# f28p65x_output_xbar_ext64_regs register map
Vendor: Texas Instruments
Peripheral module from a debugger description file (folder C2000).
Address unit: 16 bits
Registers are 32-bit, read-write, no defined reset value unless marked. A register's access mark holds for its fields unless they carry their own. Offsets are as the file gives them; lines under a group give offsets from that group; [hi:lo] are bit positions; {n}, {i} and the like mark numbered series; 'fields as' and 'values as' point back to an identical list; <NAME> marks a mode.

## OUTPUT_XBAR_EXT64_REGS — OUTPUT XBAR EXT64 Registers
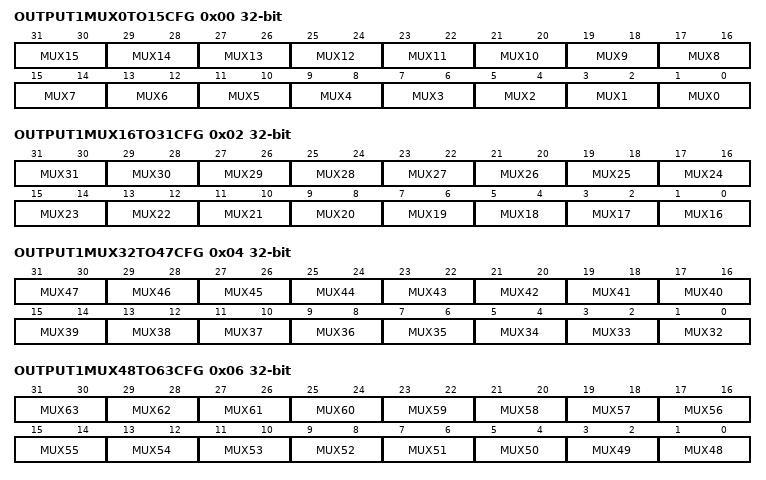
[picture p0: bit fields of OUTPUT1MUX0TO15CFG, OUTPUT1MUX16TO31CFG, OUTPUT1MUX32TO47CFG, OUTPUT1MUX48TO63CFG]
0x00 OUTPUT1MUX0TO15CFG — Output X-BAR Mux Configuration for Output 1
  [2n+1:2n] MUX{n} (n=0..15) — Mux{n} Configuration for OUTPUT1 of OUTPUT-XBAR
0x02 OUTPUT1MUX16TO31CFG — Output X-BAR Mux Configuration for Output 1
  [2n-31:2n-32] MUX{n} (n=16..31) — Mux{n} Configuration for OUTPUT1 of OUTPUT-XBAR
0x04 OUTPUT1MUX32TO47CFG — Output X-BAR Mux Configuration for Output 1
  [2n-63:2n-64] MUX{n} (n=32..47) — MUX{n} Configuration for OUTPUT1 of OUTPUT-XBAR
0x06 OUTPUT1MUX48TO63CFG — Output X-BAR Mux Configuration for Output 1
  [2n-95:2n-96] MUX{n} (n=48..63) — MUX{n} Configuration for OUTPUT1 of OUTPUT-XBAR
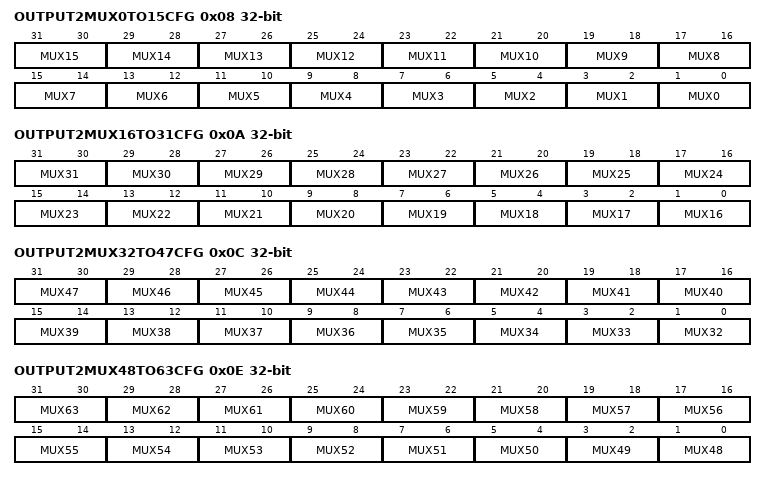
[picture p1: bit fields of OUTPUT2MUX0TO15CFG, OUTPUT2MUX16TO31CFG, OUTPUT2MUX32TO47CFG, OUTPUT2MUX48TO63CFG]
0x08 OUTPUT2MUX0TO15CFG — Output X-BAR Mux Configuration for Output 2
  [2n+1:2n] MUX{n} (n=0..15) — Mux{n} Configuration for OUTPUT2 of OUTPUT-XBAR
0x0A OUTPUT2MUX16TO31CFG — Output X-BAR Mux Configuration for Output 2
  [2n-31:2n-32] MUX{n} (n=16..31) — Mux{n} Configuration for OUTPUT2 of OUTPUT-XBAR
0x0C OUTPUT2MUX32TO47CFG — Output X-BAR Mux Configuration for Output 2
  [2n-63:2n-64] MUX{n} (n=32..47) — MUX{n} Configuration for OUTPUT2 of OUTPUT-XBAR
0x0E OUTPUT2MUX48TO63CFG — Output X-BAR Mux Configuration for Output 2
  [2n-95:2n-96] MUX{n} (n=48..63) — MUX{n} Configuration for OUTPUT2 of OUTPUT-XBAR
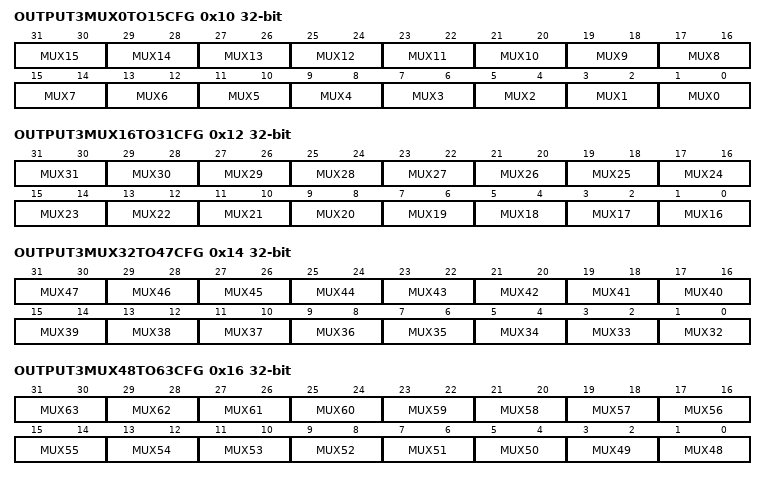
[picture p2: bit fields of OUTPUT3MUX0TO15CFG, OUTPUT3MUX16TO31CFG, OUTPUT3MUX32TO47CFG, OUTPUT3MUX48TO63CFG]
0x10 OUTPUT3MUX0TO15CFG — Output X-BAR Mux Configuration for Output 3
  [2n+1:2n] MUX{n} (n=0..15) — Mux{n} Configuration for OUTPUT3 of OUTPUT-XBAR
0x12 OUTPUT3MUX16TO31CFG — Output X-BAR Mux Configuration for Output 3
  [2n-31:2n-32] MUX{n} (n=16..31) — Mux{n} Configuration for OUTPUT3 of OUTPUT-XBAR
0x14 OUTPUT3MUX32TO47CFG — Output X-BAR Mux Configuration for Output 3
  [2n-63:2n-64] MUX{n} (n=32..47) — MUX{n} Configuration for OUTPUT3 of OUTPUT-XBAR
0x16 OUTPUT3MUX48TO63CFG — Output X-BAR Mux Configuration for Output 3
  [2n-95:2n-96] MUX{n} (n=48..63) — MUX{n} Configuration for OUTPUT3 of OUTPUT-XBAR
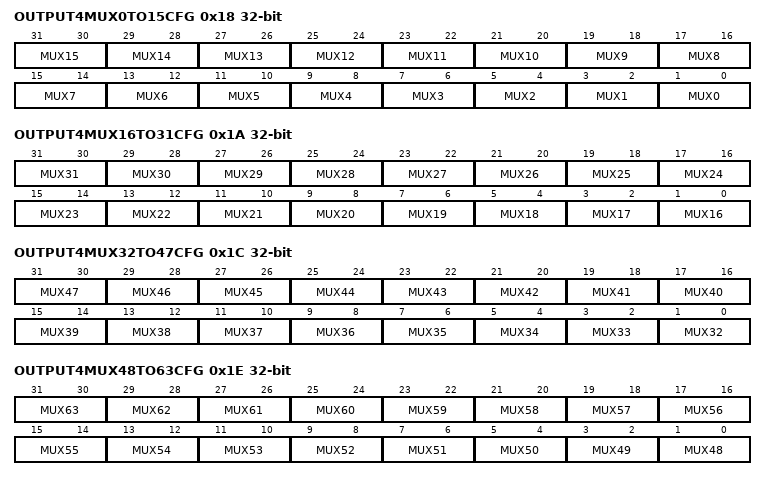
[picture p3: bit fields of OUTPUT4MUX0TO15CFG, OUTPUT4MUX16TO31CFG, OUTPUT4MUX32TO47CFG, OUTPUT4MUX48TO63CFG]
0x18 OUTPUT4MUX0TO15CFG — Output X-BAR Mux Configuration for Output 4
  [2n+1:2n] MUX{n} (n=0..15) — Mux{n} Configuration for OUTPUT4 of OUTPUT-XBAR
0x1A OUTPUT4MUX16TO31CFG — Output X-BAR Mux Configuration for Output 4
  [2n-31:2n-32] MUX{n} (n=16..31) — Mux{n} Configuration for OUTPUT4 of OUTPUT-XBAR
0x1C OUTPUT4MUX32TO47CFG — Output X-BAR Mux Configuration for Output 4
  [2n-63:2n-64] MUX{n} (n=32..47) — MUX{n} Configuration for OUTPUT4 of OUTPUT-XBAR
0x1E OUTPUT4MUX48TO63CFG — Output X-BAR Mux Configuration for Output 4
  [2n-95:2n-96] MUX{n} (n=48..63) — MUX{n} Configuration for OUTPUT4 of OUTPUT-XBAR
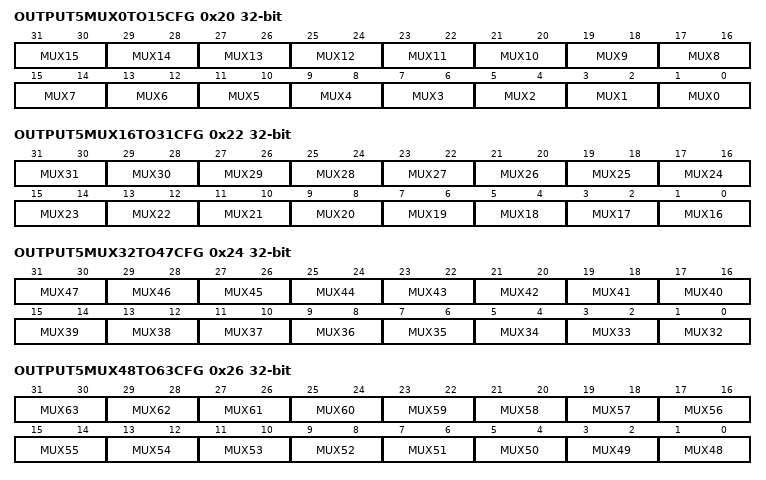
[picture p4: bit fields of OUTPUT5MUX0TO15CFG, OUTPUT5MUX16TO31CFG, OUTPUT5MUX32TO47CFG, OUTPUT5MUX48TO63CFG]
0x20 OUTPUT5MUX0TO15CFG — Output X-BAR Mux Configuration for Output 5
  [2n+1:2n] MUX{n} (n=0..15) — Mux{n} Configuration for OUTPUT5 of OUTPUT-XBAR
0x22 OUTPUT5MUX16TO31CFG — Output X-BAR Mux Configuration for Output 5
  [2n-31:2n-32] MUX{n} (n=16..31) — Mux{n} Configuration for OUTPUT5 of OUTPUT-XBAR
0x24 OUTPUT5MUX32TO47CFG — Output X-BAR Mux Configuration for Output 5
  [2n-63:2n-64] MUX{n} (n=32..47) — MUX{n} Configuration for OUTPUT5 of OUTPUT-XBAR
0x26 OUTPUT5MUX48TO63CFG — Output X-BAR Mux Configuration for Output 5
  [2n-95:2n-96] MUX{n} (n=48..63) — MUX{n} Configuration for OUTPUT5 of OUTPUT-XBAR
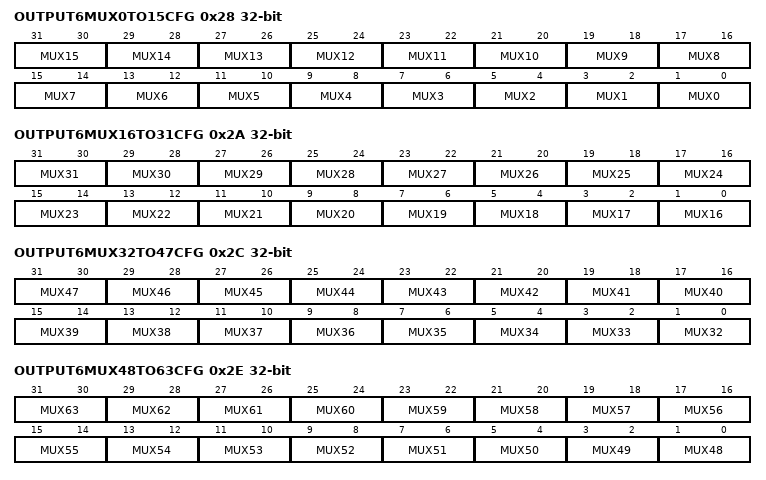
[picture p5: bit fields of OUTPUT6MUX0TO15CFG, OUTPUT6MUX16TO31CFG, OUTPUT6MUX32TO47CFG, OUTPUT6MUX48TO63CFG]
0x28 OUTPUT6MUX0TO15CFG — Output X-BAR Mux Configuration for Output 6
  [2n+1:2n] MUX{n} (n=0..15) — Mux{n} Configuration for OUTPUT6 of OUTPUT-XBAR
0x2A OUTPUT6MUX16TO31CFG — Output X-BAR Mux Configuration for Output 6
  [2n-31:2n-32] MUX{n} (n=16..31) — Mux{n} Configuration for OUTPUT6 of OUTPUT-XBAR
0x2C OUTPUT6MUX32TO47CFG — Output X-BAR Mux Configuration for Output 6
  [2n-63:2n-64] MUX{n} (n=32..47) — MUX{n} Configuration for OUTPUT6 of OUTPUT-XBAR
0x2E OUTPUT6MUX48TO63CFG — Output X-BAR Mux Configuration for Output 6
  [2n-95:2n-96] MUX{n} (n=48..63) — MUX{n} Configuration for OUTPUT6 of OUTPUT-XBAR
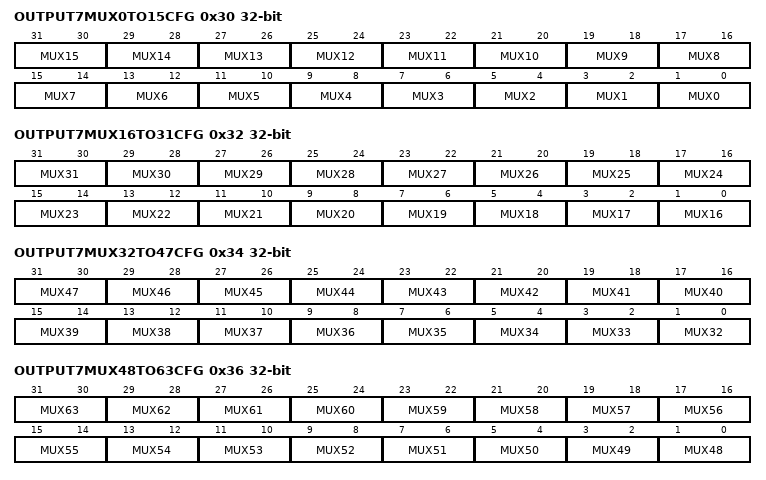
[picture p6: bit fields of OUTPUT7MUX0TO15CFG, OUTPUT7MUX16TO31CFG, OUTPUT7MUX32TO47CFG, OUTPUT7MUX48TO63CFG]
0x30 OUTPUT7MUX0TO15CFG — Output X-BAR Mux Configuration for Output 7
  [2n+1:2n] MUX{n} (n=0..15) — Mux{n} Configuration for OUTPUT7 of OUTPUT-XBAR
0x32 OUTPUT7MUX16TO31CFG — Output X-BAR Mux Configuration for Output 7
  [2n-31:2n-32] MUX{n} (n=16..31) — Mux{n} Configuration for OUTPUT7 of OUTPUT-XBAR
0x34 OUTPUT7MUX32TO47CFG — Output X-BAR Mux Configuration for Output 7
  [2n-63:2n-64] MUX{n} (n=32..47) — MUX{n} Configuration for OUTPUT7 of OUTPUT-XBAR
0x36 OUTPUT7MUX48TO63CFG — Output X-BAR Mux Configuration for Output 7
  [2n-95:2n-96] MUX{n} (n=48..63) — MUX{n} Configuration for OUTPUT7 of OUTPUT-XBAR
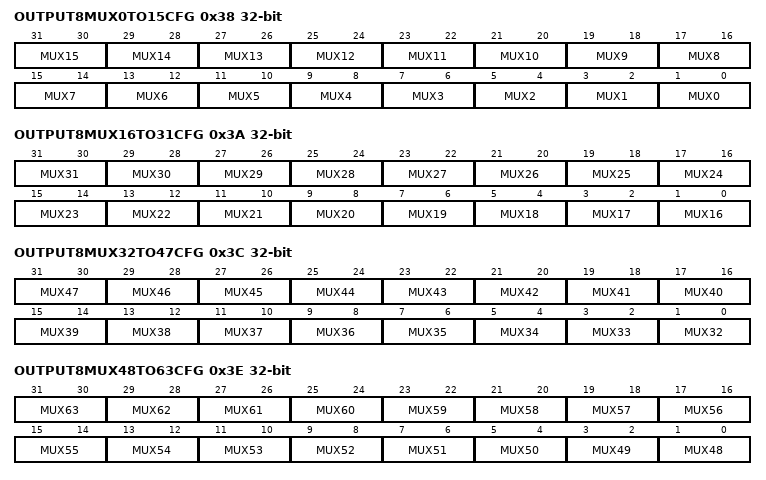
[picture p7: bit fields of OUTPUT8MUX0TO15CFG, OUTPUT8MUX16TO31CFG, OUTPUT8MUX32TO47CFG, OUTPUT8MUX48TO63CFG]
0x38 OUTPUT8MUX0TO15CFG — Output X-BAR Mux Configuration for Output 8
  [2n+1:2n] MUX{n} (n=0..15) — Mux{n} Configuration for OUTPUT8 of OUTPUT-XBAR
0x3A OUTPUT8MUX16TO31CFG — Output X-BAR Mux Configuration for Output 8
  [2n-31:2n-32] MUX{n} (n=16..31) — Mux{n} Configuration for OUTPUT8 of OUTPUT-XBAR
0x3C OUTPUT8MUX32TO47CFG — Output X-BAR Mux Configuration for Output 8
  [2n-63:2n-64] MUX{n} (n=32..47) — MUX{n} Configuration for OUTPUT8 of OUTPUT-XBAR
0x3E OUTPUT8MUX48TO63CFG — Output X-BAR Mux Configuration for Output 8
  [2n-95:2n-96] MUX{n} (n=48..63) — MUX{n} Configuration for OUTPUT8 of OUTPUT-XBAR
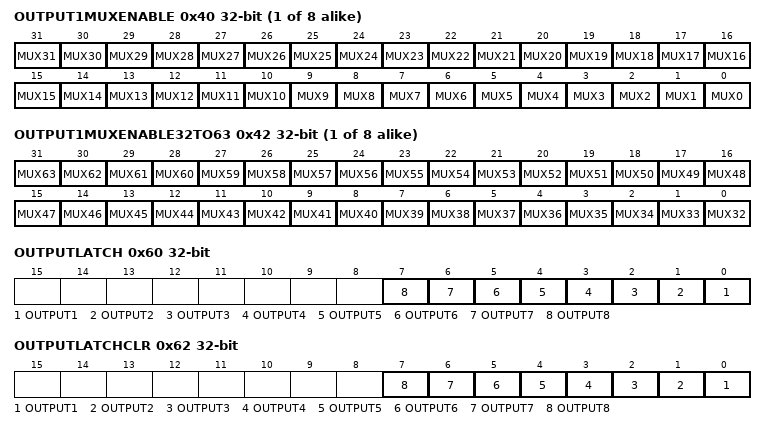
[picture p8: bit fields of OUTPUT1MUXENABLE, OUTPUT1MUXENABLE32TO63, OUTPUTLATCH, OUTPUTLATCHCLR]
{0x3C+4i} OUTPUT{i}MUXENABLE (i=1..8) — Output X-BAR Mux Enable for Output {i}
  [n] MUX{n} (n=0..31) — Mux{n} to drive OUTPUT{i} of OUTPUT-XBAR
{0x3E+4i} OUTPUT{i}MUXENABLE32TO63 (i=1..8) — Output X-BAR Mux Enable for Output {i}
  [n-32] MUX{n} (n=32..63) — MUX{n} to drive OUTPUT{i} of OUTPUT-XBAR
0x60 OUTPUTLATCH ro — Output X-BAR Output Latch
  [n-1] OUTPUT{n} (n=1..8) — Records the OUTPUT{n} of OUTPUT-XBAR
0x62 OUTPUTLATCHCLR — Output X-BAR Output Latch Clear
  [n-1] OUTPUT{n} (n=1..8) — Clears the Output-Latch for OUTPUT{n} of OUTPUT-XBAR
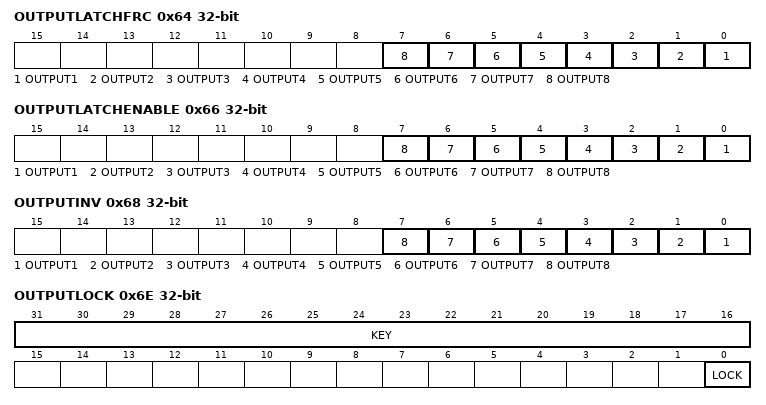
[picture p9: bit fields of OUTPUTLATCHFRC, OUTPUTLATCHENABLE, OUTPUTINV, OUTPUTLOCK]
0x64 OUTPUTLATCHFRC — Output X-BAR Output Latch Clear
  [n-1] OUTPUT{n} (n=1..8) — Sets the Output-Latch for OUTPUT{n} of OUTPUT-XBAR
0x66 OUTPUTLATCHENABLE — Output X-BAR Output Latch Enable
  [n-1] OUTPUT{n} (n=1..8) — Selects the output latch to drive OUTPUT{n} for OUTPUT-XBAR
0x68 OUTPUTINV — Output X-BAR Output Inversion
  [n-1] OUTPUT{n} (n=1..8) — Selects polarity for OUTPUT{n} of OUTPUT-XBAR
0x6E OUTPUTLOCK — Output X-BAR Configuration Lock register
  [31:16] KEY — Write Protection KEY
  [0] LOCK — Locks the configuration for OUTPUT-XBAR
